# nRF54h20_secure register map
Vendor: Nordic Semiconductor; Series: nRF54h; File version: 1
CPU: CM33 r0p4, little endian, MPU, no FPU, 3 interrupt priority bits, 480 interrupts, 8 SAU regions
Registers are 32-bit, read-write, reset 0x0 unless marked. A register's access mark holds for its fields unless they carry their own. Offsets are from the block's base; [hi:lo] are bit positions; lines under a group give offsets from that group; {n}, {i} and the like mark numbered series; 'fields as' and 'values as' point back to an identical list.

## GLOBAL_RAMC122_NS — RAM Controller 0
Base 0x4F8DA000
Same registers: GLOBAL_RAMC122_S 0x5F8DA000
0x500 WAITSTATES — Waitstates for read operations.
  [0] WAITSTATES — Number of waitstates for a read from the RAM.

## GLOBAL_DPPIC120_NS — Distributed programmable peripheral interconnect controller 0
Base 0x4F8E1000
Same registers: GLOBAL_DPPIC130_NS 0x4F922000, GLOBAL_DPPIC131_NS 0x4F981000, GLOBAL_DPPIC132_NS 0x4F991000, GLOBAL_DPPIC133_NS 0x4F9A1000, GLOBAL_DPPIC134_NS 0x4F9B1000, GLOBAL_DPPIC135_NS 0x4F9C1000, GLOBAL_DPPIC136_NS 0x4F9D1000, GLOBAL_DPPIC120_S 0x5F8E1000, GLOBAL_DPPIC130_S 0x5F922000, GLOBAL_DPPIC131_S 0x5F981000, GLOBAL_DPPIC132_S 0x5F991000, GLOBAL_DPPIC133_S 0x5F9A1000, GLOBAL_DPPIC134_S 0x5F9B1000, GLOBAL_DPPIC135_S 0x5F9C1000, GLOBAL_DPPIC136_S 0x5F9D1000
{0x0+8i} TASKS_CHG[{i}] (i=0..3) group — Channel group tasks
  0x00 EN wo — Description cluster: Enable channel group n
    [0] EN — Enable channel group n
      1=Trigger task
  0x04 DIS wo — Description cluster: Disable channel group n
    [0] DIS — Disable channel group n
      1=Trigger task
{0x80+8i} SUBSCRIBE_CHG[{i}] (i=0..3) group — Subscribe configuration for tasks
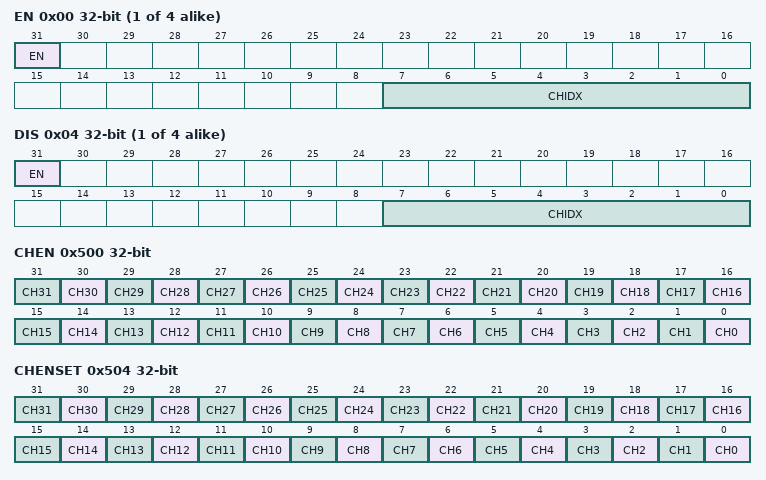
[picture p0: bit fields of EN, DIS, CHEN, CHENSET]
  0x00 EN — Description cluster: Subscribe configuration for task CHG[n].EN
    [31] EN
      0=Disabled (Disable subscription); 1=Enabled (Enable subscription)
    [7:0] CHIDX — DPPI channel that task CHG[n].EN will subscribe to
  0x04 DIS — Description cluster: Subscribe configuration for task CHG[n].DIS
    [31] EN
      values as SUBSCRIBE_CHG[0].EN.EN
    [7:0] CHIDX — DPPI channel that task CHG[n].DIS will subscribe to
0x500 CHEN — Channel enable register
  [all] fields
    0=Disabled (Disable channel); 1=Enabled (Enable channel)
  [n] CH{n} (n=0..31) — Enable or disable channel {n}
0x504 CHENSET write-1-sets — Channel enable set register
  [all] fields
    on read: 0=Disabled (Read: Channel disabled); 1=Enabled (Read: Channel enabled) | on write: 1=Set (Write: Enable channel)
  [n] CH{n} (n=0..31) — Channel {n} enable set register. Writing 0 has no effect.
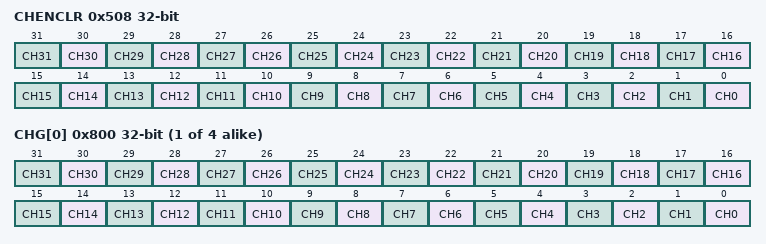
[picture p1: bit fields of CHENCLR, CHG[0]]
0x508 CHENCLR write-1-clears — Channel enable clear register
  [all] fields
    on read: 0=Disabled (Read: Channel disabled); 1=Enabled (Read: Channel enabled) | on write: 1=Clear (Write: Disable channel)
  [n] CH{n} (n=0..31) — Channel {n} enable clear register. Writing 0 has no effect.
{0x800+4i} CHG[{i}] (i=0..3) — Description collection: Channel group n Note: Writes to this register are ignored if either SUBSCRIBE_CHG[n].EN or SUBSCRIBE_CHG[n].DIS is enabled
  [all] fields
    0=Excluded; 1=Included
  [n] CH{n} (n=0..31) — Include or exclude channel {n}

## IPCMAP_S — IPCMAP registers
Base 0x5F923000
{0x400+8i} CHANNEL[{i}] (i=0..15) group — Unspecified
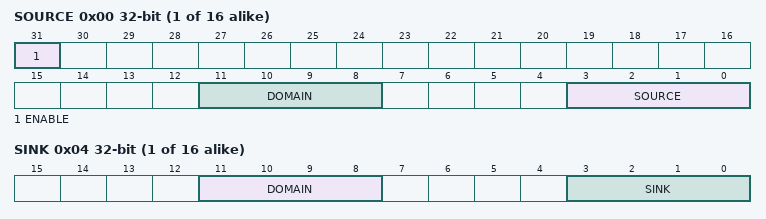
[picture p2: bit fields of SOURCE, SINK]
  0x00 SOURCE — Description cluster: The IPCT source configuration for the IPCMAP channel [n].
    [31] ENABLE — Channel enable.
      0=Disabled (Disable channel.); 1=Enabled (Enable channel.)
    [11:8] DOMAIN — Domain identifier.
    [3:0] SOURCE — Source IPCT channel number.
  0x04 SINK — Description cluster: The IPCT sink configuration for the IPCMAP channel [n].
    [11:8] DOMAIN — Domain identifier.
    [3:0] SINK — Sink IPCT channel number.

## IRQMAP_S — IRQMAP APB registers
Base 0x5F924000
{0x400+4i} IRQ[{i}] (i=0..479) group — Unspecified
  0x00 SINK — Description cluster: The interrupt sink configuration for Global Domain IRQ [n: Global ID] to a processor.
    [11:8] PROCESSORID

## GLOBAL_EGU130_NS — Event generator unit 0
Base 0x4F92D000
Same registers: GLOBAL_EGU130_S 0x5F92D000
{0x0+4i} TASKS_TRIGGER[{i}] (i=0..15) wo — Description collection: Trigger n for triggering the corresponding TRIGGERED[n] event
  [0] TASKS_TRIGGER — Trigger n for triggering the corresponding TRIGGERED[n] event
    1=Trigger task
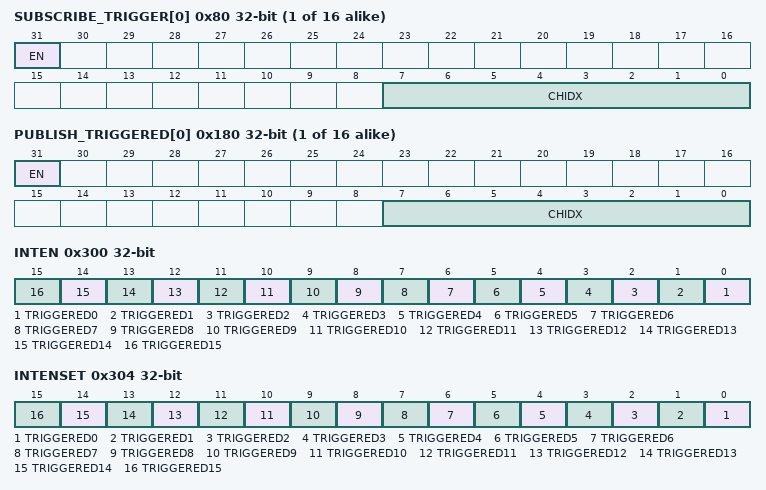
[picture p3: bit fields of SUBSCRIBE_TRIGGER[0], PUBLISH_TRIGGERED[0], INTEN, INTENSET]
{0x80+4i} SUBSCRIBE_TRIGGER[{i}] (i=0..15) — Description collection: Subscribe configuration for task TRIGGER[n]
  [31] EN
    0=Disabled (Disable subscription); 1=Enabled (Enable subscription)
  [7:0] CHIDX — DPPI channel that task TRIGGER[n] will subscribe to
{0x100+4i} EVENTS_TRIGGERED[{i}] (i=0..15) — Description collection: Event number n generated by triggering the corresponding TRIGGER[n] task
  [0] EVENTS_TRIGGERED — Event number n generated by triggering the corresponding TRIGGER[n] task
    0=NotGenerated (Event not generated); 1=Generated (Event generated)
{0x180+4i} PUBLISH_TRIGGERED[{i}] (i=0..15) — Description collection: Publish configuration for event TRIGGERED[n]
  [31] EN
    0=Disabled (Disable publishing); 1=Enabled (Enable publishing)
  [7:0] CHIDX — DPPI channel that event TRIGGERED[n] will publish to
0x300 INTEN — Enable or disable interrupt
  [all] fields
    0=Disabled; 1=Enabled
  [n] TRIGGERED{n} (n=0..15) — Enable or disable interrupt for event TRIGGERED[{n}]
0x304 INTENSET — Enable interrupt
  [all] fields
    on read: 0=Disabled (Read: Disabled); 1=Enabled (Read: Enabled) | on write: 1=Set (Enable)
  [n] TRIGGERED{n} (n=0..15) — Write '1' to enable interrupt for event TRIGGERED[{n}]
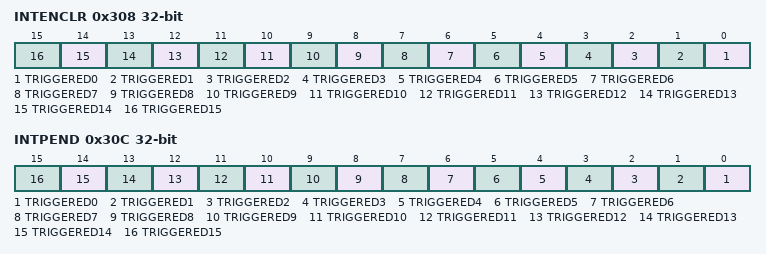
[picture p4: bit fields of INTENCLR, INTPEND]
0x308 INTENCLR — Disable interrupt
  [all] fields
    on read: 0=Disabled (Read: Disabled); 1=Enabled (Read: Enabled) | on write: 1=Clear (Disable)
  [n] TRIGGERED{n} (n=0..15) — Write '1' to disable interrupt for event TRIGGERED[{n}]
0x30C INTPEND ro — Pending interrupts
  [all] fields
    on read: 0=NotPending (Read: Not pending); 1=Pending (Read: Pending)
  [n] TRIGGERED{n} (n=0..15) — Read pending status of interrupt for event TRIGGERED[{n}]

## GLOBAL_TEMP_NS — Temperature Sensor 0
Base 0x4F984000
Same registers: GLOBAL_TEMP_S 0x5F984000
0x00 TASKS_START wo — Start temperature measurement
  [0] TASKS_START
    1=Trigger task
0x04 TASKS_STOP wo — Stop temperature measurement
  [0] TASKS_STOP
    1=Trigger task
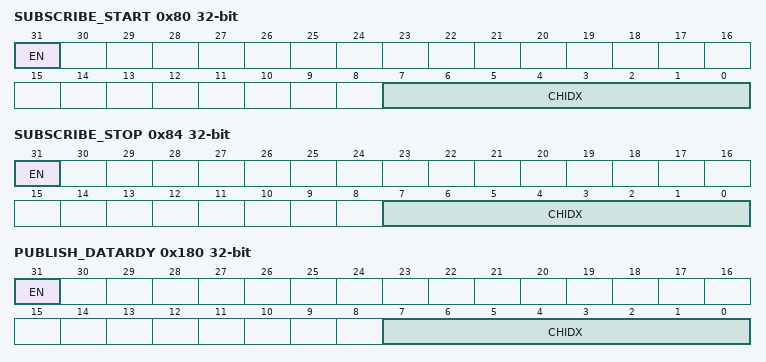
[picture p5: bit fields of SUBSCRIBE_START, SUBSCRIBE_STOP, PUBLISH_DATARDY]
0x80 SUBSCRIBE_START — Subscribe configuration for task START
  [31] EN
    0=Disabled (Disable subscription); 1=Enabled (Enable subscription)
  [7:0] CHIDX — DPPI channel that task START will subscribe to
0x84 SUBSCRIBE_STOP — Subscribe configuration for task STOP
  [31] EN
    values as SUBSCRIBE_START.EN
  [7:0] CHIDX — DPPI channel that task STOP will subscribe to
0x100 EVENTS_DATARDY — Temperature measurement complete, data ready
  [0] EVENTS_DATARDY
    0=NotGenerated (Event not generated); 1=Generated (Event generated)
0x180 PUBLISH_DATARDY — Publish configuration for event DATARDY
  [31] EN
    0=Disabled (Disable publishing); 1=Enabled (Enable publishing)
  [7:0] CHIDX — DPPI channel that event DATARDY will publish to
0x304 INTENSET — Enable interrupt
  [0] DATARDY — Write '1' to enable interrupt for event DATARDY
    on read: 0=Disabled (Read: Disabled); 1=Enabled (Read: Enabled) | on write: 1=Set (Enable)
0x308 INTENCLR — Disable interrupt
  [0] DATARDY — Write '1' to disable interrupt for event DATARDY
    on read: 0=Disabled (Read: Disabled); 1=Enabled (Read: Enabled) | on write: 1=Clear (Disable)
0x508 TEMP ro — Temperature in degC (0.25deg steps)
0x520 A0 reset 0x276 — Slope of 1st piece wise linear function
  [11:0] A0
0x524 A1 reset 0x324 — Slope of 2nd piece wise linear function
  [11:0] A1
0x528 A2 reset 0x3AB — Slope of 3rd piece wise linear function
  [11:0] A2
0x52C A3 reset 0x453 — Slope of 4th piece wise linear function
  [11:0] A3
0x530 A4 reset 0x49B — Slope of 5th piece wise linear function
  [11:0] A4
0x534 A5 reset 0x550 — Slope of 6th piece wise linear function
  [11:0] A5
0x538 A6 reset 0x67E — Slope of 7th piece wise linear function
  [11:0] A6
0x540 B0 reset 0xFA6 — y-intercept of 1st piece wise linear function
  [11:0] B0
0x544 B1 reset 0xF35 — y-intercept of 2nd piece wise linear function
  [11:0] B1
0x548 B2 reset 0xFAA — y-intercept of 3rd piece wise linear function
  [11:0] B2
0x54C B3 reset 0x7E — y-intercept of 4th piece wise linear function
  [11:0] B3
0x550 B4 reset 0xEA — y-intercept of 5th piece wise linear function
  [11:0] B4
0x554 B5 reset 0x1ED — y-intercept of 6th piece wise linear function
  [11:0] B5
0x558 B6 reset 0x378 — y-intercept of 7th piece wise linear function
  [11:0] B6
0x560 T0 reset 0xED — End point of 1st piece wise linear function
  [7:0] T0
0x564 T1 reset 0x13 — End point of 2nd piece wise linear function
  [7:0] T1
0x568 T2 reset 0x29 — End point of 3rd piece wise linear function
  [7:0] T2
0x56C T3 reset 0x3C — End point of 4th piece wise linear function
  [7:0] T3
0x570 T4 reset 0x44 — End point of 5th piece wise linear function
  [7:0] T4
0x574 T5 reset 0x53 — End point of 6th piece wise linear function
  [7:0] T5
